# EFM32PG1B register map
File version: 5.8.2
CPU: CM4 r0p1, little endian, MPU, FPU, 3 interrupt priority bits
Registers are 32-bit, read-write, reset 0x0 unless marked. A register's access mark holds for its fields unless they carry their own. Offsets are from the block's base; [hi:lo] are bit positions; lines under a group give offsets from that group; {n}, {i} and the like mark numbered series; 'fields as' and 'values as' point back to an identical list.

## GPIO
Base 0x4000A000
0x00 PORT_A group — Port A Registers
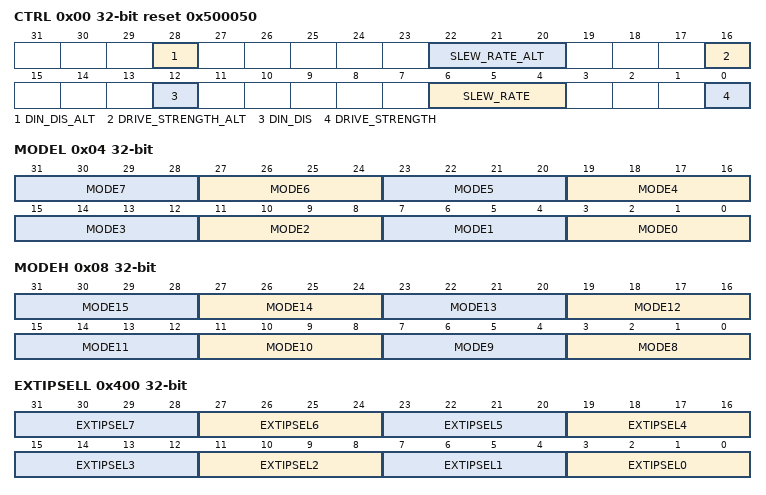
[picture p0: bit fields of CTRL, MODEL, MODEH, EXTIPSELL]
  0x00 CTRL reset 0x500050 — Port Control Register
    [28] DIN_DIS_ALT — Alternate Data in Disable
    [22:20] SLEW_RATE_ALT — Slewrate limit for port pins using alternate modes. Higher values represent faster slewrates
    [16] DRIVE_STRENGTH_ALT — Drive strength setting for port pins using alternate modes. Value `0` is STRONG (10mA), value `1` is WEAK (1mA)
    [12] DIN_DIS — Data in Disable
    [6:4] SLEW_RATE — Slewrate limit for port pins not using alternate modes. Higher values represent faster slewrates
    [0] DRIVE_STRENGTH — Drive strength setting for port pins not using alternate modes. Value `0` is STRONG (10mA), value `1` is WEAK (1mA)
  0x04 MODEL — Port Pin Mode Low Register
    [all] fields
      0=DISABLED (Input disabled. Pullup if DOUT is set.); 1=INPUT (Input enabled. Filter if DOUT is set); 2=INPUTPULL (Input enabled. DOUT determines pull direction); 3=INPUTPULLFILTER (Input enabled with filter. DOUT determines pull direction); 4=PUSHPULL (Push-pull output); 5=PUSHPULLALT (Push-pull using alternate control); 6=WIREDOR (Wired-or output); 7=WIREDORPULLDOWN (Wired-or output with pull-down); 8=WIREDAND (Open-drain output); 9=WIREDANDFILTER (Open-drain output with filter); 10=WIREDANDPULLUP (Open-drain output with pullup); 11=WIREDANDPULLUPFILTER (Open-drain output with filter and pullup); 12=WIREDANDALT (Open-drain output using alternate control); 13=WIREDANDALTFILTER (Open-drain output using alternate control with filter); 14=WIREDANDALTPULLUP (Open-drain output using alternate control with pullup); 15=WIREDANDALTPULLUPFILTER (Open-drain output using alternate control with filter and pullup)
    [4n+3:4n] MODE{n} (n=0..7) — Pin {n} Mode
  0x08 MODEH — Port Pin Mode High Register
    [all] fields
      values as the fields of PORT_A.MODEL
    [4n-29:4n-32] MODE{n} (n=8..15) — Pin {n} Mode
  0x0C DOUT — Port Data Out Register
    [15:0] PINS_DOUT — Data Out for pins 0:15
  0x18 DOUT_TGL wo — Port Data Out Toggle Register. Write bits to 1 to toggle corresponding bits in GPIO_Px_DOUT. Bits written to 0 will have no effect.
    [15:0] PINS_DOUT_TGL — Data Out Toggle for pins 0:15
  0x1C DIN ro — Port Data in Register
    [15:0] PINS_DIN — Data in for pins 0:15
  0x20 PINLOCKN reset 0xFFFF — Port Unlocked Pins Register. Shows unlocked pins in the port. To lock pin n, clear bit n. The pin is then locked until reset.
    [15:0] PINS_PINLOCKN — Unlocked Pins for pins 0:15
  0x28 OVT_DIS — Over Voltage Disable for All Modes
    [15:0] PINS_OVT_DIS — Disable Over Voltage Capability for pins 0:15
0x30 PORT_B group — Port B Registers
  0x00 CTRL reset 0x500050 — Port Control Register
    fields as PORT_A.CTRL
  0x04 MODEL — Port Pin Mode Low Register
    fields as PORT_A.MODEL
  0x08 MODEH — Port Pin Mode High Register
    fields as PORT_A.MODEH
  0x0C DOUT — Port Data Out Register
    [15:0] PINS_DOUT — Data Out for pins 0:15
  0x18 DOUT_TGL wo — Port Data Out Toggle Register. Write bits to 1 to toggle corresponding bits in GPIO_Px_DOUT. Bits written to 0 will have no effect.
    [15:0] PINS_DOUT_TGL — Data Out Toggle for pins 0:15
  0x1C DIN ro — Port Data in Register
    [15:0] PINS_DIN — Data in for pins 0:15
  0x20 PINLOCKN reset 0xFFFF — Port Unlocked Pins Register. Shows unlocked pins in the port. To lock pin n, clear bit n. The pin is then locked until reset.
    [15:0] PINS_PINLOCKN — Unlocked Pins for pins 0:15
  0x28 OVT_DIS — Over Voltage Disable for All Modes
    [15:0] PINS_OVT_DIS — Disable Over Voltage Capability for pins 0:15
0x60 PORT_C group — Port C Registers
  0x00 CTRL reset 0x500050 — Port Control Register
    fields as PORT_A.CTRL
  0x04 MODEL — Port Pin Mode Low Register
    fields as PORT_A.MODEL
  0x08 MODEH — Port Pin Mode High Register
    fields as PORT_A.MODEH
  0x0C DOUT — Port Data Out Register
    [15:0] PINS_DOUT — Data Out for pins 0:15
  0x18 DOUT_TGL wo — Port Data Out Toggle Register. Write bits to 1 to toggle corresponding bits in GPIO_Px_DOUT. Bits written to 0 will have no effect.
    [15:0] PINS_DOUT_TGL — Data Out Toggle for pins 0:15
  0x1C DIN ro — Port Data in Register
    [15:0] PINS_DIN — Data in for pins 0:15
  0x20 PINLOCKN reset 0xFFFF — Port Unlocked Pins Register. Shows unlocked pins in the port. To lock pin n, clear bit n. The pin is then locked until reset.
    [15:0] PINS_PINLOCKN — Unlocked Pins for pins 0:15
  0x28 OVT_DIS — Over Voltage Disable for All Modes
    [15:0] PINS_OVT_DIS — Disable Over Voltage Capability for pins 0:15
0x90 PORT_D group — Port D Registers
  0x00 CTRL reset 0x500050 — Port Control Register
    fields as PORT_A.CTRL
  0x04 MODEL — Port Pin Mode Low Register
    fields as PORT_A.MODEL
  0x08 MODEH — Port Pin Mode High Register
    fields as PORT_A.MODEH
  0x0C DOUT — Port Data Out Register
    [15:0] PINS_DOUT — Data Out for pins 0:15
  0x18 DOUT_TGL wo — Port Data Out Toggle Register. Write bits to 1 to toggle corresponding bits in GPIO_Px_DOUT. Bits written to 0 will have no effect.
    [15:0] PINS_DOUT_TGL — Data Out Toggle for pins 0:15
  0x1C DIN ro — Port Data in Register
    [15:0] PINS_DIN — Data in for pins 0:15
  0x20 PINLOCKN reset 0xFFFF — Port Unlocked Pins Register. Shows unlocked pins in the port. To lock pin n, clear bit n. The pin is then locked until reset.
    [15:0] PINS_PINLOCKN — Unlocked Pins for pins 0:15
  0x28 OVT_DIS — Over Voltage Disable for All Modes
    [15:0] PINS_OVT_DIS — Disable Over Voltage Capability for pins 0:15
0xC0 PORT_E group — Port E Registers
  0x00 CTRL reset 0x500050 — Port Control Register
    fields as PORT_A.CTRL
  0x04 MODEL — Port Pin Mode Low Register
    fields as PORT_A.MODEL
  0x08 MODEH — Port Pin Mode High Register
    fields as PORT_A.MODEH
  0x0C DOUT — Port Data Out Register
    [15:0] PINS_DOUT — Data Out for pins 0:15
  0x18 DOUT_TGL wo — Port Data Out Toggle Register. Write bits to 1 to toggle corresponding bits in GPIO_Px_DOUT. Bits written to 0 will have no effect.
    [15:0] PINS_DOUT_TGL — Data Out Toggle for pins 0:15
  0x1C DIN ro — Port Data in Register
    [15:0] PINS_DIN — Data in for pins 0:15
  0x20 PINLOCKN reset 0xFFFF — Port Unlocked Pins Register. Shows unlocked pins in the port. To lock pin n, clear bit n. The pin is then locked until reset.
    [15:0] PINS_PINLOCKN — Unlocked Pins for pins 0:15
  0x28 OVT_DIS — Over Voltage Disable for All Modes
    [15:0] PINS_OVT_DIS — Disable Over Voltage Capability for pins 0:15
0xF0 PORT_F group — Port F Registers
  0x00 CTRL reset 0x500050 — Port Control Register
    fields as PORT_A.CTRL
  0x04 MODEL — Port Pin Mode Low Register
    fields as PORT_A.MODEL
  0x08 MODEH — Port Pin Mode High Register
    fields as PORT_A.MODEH
  0x0C DOUT — Port Data Out Register
    [15:0] PINS_DOUT — Data Out for pins 0:15
  0x18 DOUT_TGL wo — Port Data Out Toggle Register. Write bits to 1 to toggle corresponding bits in GPIO_Px_DOUT. Bits written to 0 will have no effect.
    [15:0] PINS_DOUT_TGL — Data Out Toggle for pins 0:15
  0x1C DIN ro — Port Data in Register
    [15:0] PINS_DIN — Data in for pins 0:15
  0x20 PINLOCKN reset 0xFFFF — Port Unlocked Pins Register. Shows unlocked pins in the port. To lock pin n, clear bit n. The pin is then locked until reset.
    [15:0] PINS_PINLOCKN — Unlocked Pins for pins 0:15
  0x28 OVT_DIS — Over Voltage Disable for All Modes
    [15:0] PINS_OVT_DIS — Disable Over Voltage Capability for pins 0:15
0x400 EXTIPSELL — External Interrupt Port Select Low Register
  [4n+3:4n] EXTIPSEL{n} (n=0..7) — External Interrupt {n} Port Select
    0=PORTA (Port A group selected for external interrupt {n}); 1=PORTB (Port B group selected for external interrupt {n}); 2=PORTC (Port C group selected for external interrupt {n}); 3=PORTD (Port D group selected for external interrupt {n}); 5=PORTF (Port F group selected for external interrupt {n})
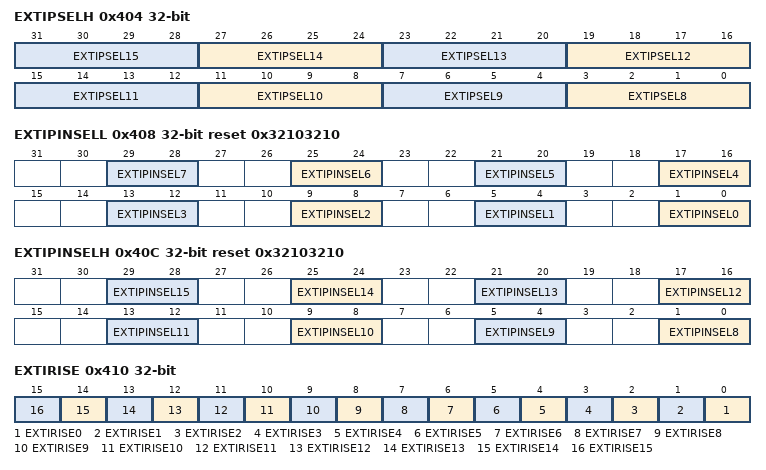
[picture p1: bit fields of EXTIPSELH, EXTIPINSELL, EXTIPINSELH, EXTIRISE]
0x404 EXTIPSELH — External Interrupt Port Select High Register
  [4n-29:4n-32] EXTIPSEL{n} (n=8..15) — External Interrupt {n} Port Select
    values as EXTIPSELL.EXTIPSEL0
0x408 EXTIPINSELL reset 0x32103210 — External Interrupt Pin Select Low Register
  [4n+1:4n] EXTIPINSEL{n} (n=4..7) — External Interrupt {n} Pin Select
    {v}=PIN{v+4} (v=0..3)
  [4n+1:4n] EXTIPINSEL{n} (n=0..3) — External Interrupt {n} Pin Select
    {v}=PIN{v} (v=0..3)
0x40C EXTIPINSELH reset 0x32103210 — External Interrupt Pin Select High Register
  [4n-31:4n-32] EXTIPINSEL{n} (n=12..15) — External Interrupt {n} Pin Select
    {v}=PIN{v+12} (v=0..3)
  [4n-31:4n-32] EXTIPINSEL{n} (n=8..11) — External Interrupt {n} Pin Select
    {v}=PIN{v+8} (v=0..3)
0x410 EXTIRISE — External Interrupt Rising Edge Trigger Register
  [n] EXTIRISE{n} (n=0..15) — Pin {n} Rising Edge Enable
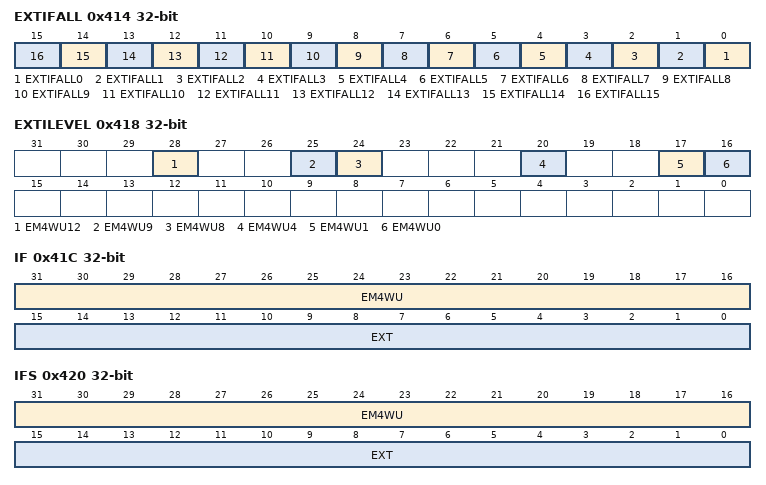
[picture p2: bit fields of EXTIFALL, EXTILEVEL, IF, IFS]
0x414 EXTIFALL — External Interrupt Falling Edge Trigger Register
  [n] EXTIFALL{n} (n=0..15) — Pin {n} Falling Edge
0x418 EXTILEVEL — External Interrupt Level Register
  [28] EM4WU12 — EM4 Wake Up Level for EM4WU12 Pin
  [25] EM4WU9 — EM4 Wake Up Level for EM4WU9 Pin
  [24] EM4WU8 — EM4 Wake Up Level for EM4WU8 Pin
  [20] EM4WU4 — EM4 Wake Up Level for EM4WU4 Pin
  [17] EM4WU1 — EM4 Wake Up Level for EM4WU1 Pin
  [16] EM4WU0 — EM4 Wake Up Level for EM4WU0 Pin
0x41C IF ro — Interrupt Flag Register
  [31:16] EM4WU — EM4 Wake Up Pin Interrupt Flag
  [15:0] EXT — External Pin Interrupt Flag
0x420 IFS wo — Interrupt Flag Set Register
  [31:16] EM4WU — Set EM4WU Interrupt Flag
  [15:0] EXT — Set EXT Interrupt Flag
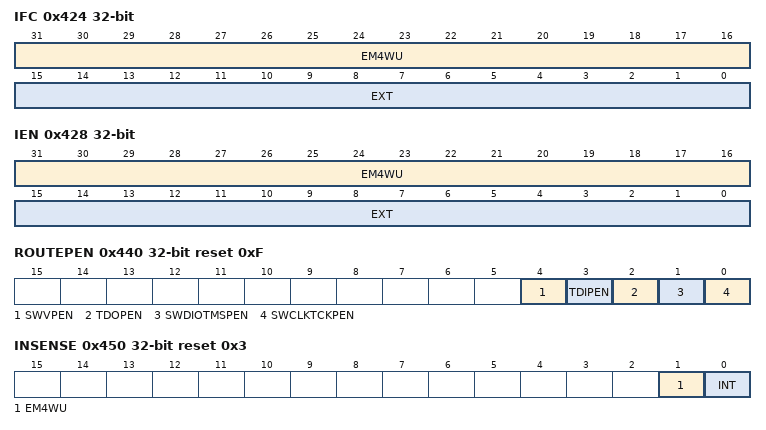
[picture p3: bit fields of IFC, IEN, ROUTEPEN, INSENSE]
0x424 IFC wo — Interrupt Flag Clear Register
  [31:16] EM4WU — Clear EM4WU Interrupt Flag
  [15:0] EXT — Clear EXT Interrupt Flag
0x428 IEN — Interrupt Enable Register
  [31:16] EM4WU — EM4WU Interrupt Enable
  [15:0] EXT — EXT Interrupt Enable
0x42C EM4WUEN — EM4 Wake Up Enable Register
  [31:16] EM4WUEN — EM4 Wake Up Enable
0x440 ROUTEPEN reset 0xF — I/O Routing Pin Enable Register
  [4] SWVPEN — Serial Wire Viewer Output Pin Enable
  [3] TDIPEN — JTAG Test Debug Input Pin Enable
  [2] TDOPEN — JTAG Test Debug Output Pin Enable
  [1] SWDIOTMSPEN — Serial Wire Data and JTAG Test Mode Select Pin Enable
  [0] SWCLKTCKPEN — Serial Wire Clock and JTAG Test Clock Pin Enable
0x444 ROUTELOC0 — I/O Routing Location Register
  [5:0] SWVLOC — I/O Location
    {v}=LOC{v} (Location {v}) (v=0..3)
0x450 INSENSE reset 0x3 — Input Sense Register
  [1] EM4WU — EM4WU Interrupt Sense Enable
  [0] INT — Interrupt Sense Enable
0x454 LOCK — Configuration Lock Register
  [15:0] LOCKKEY — Configuration Lock Key
    0=UNLOCKED; 1=LOCKED
